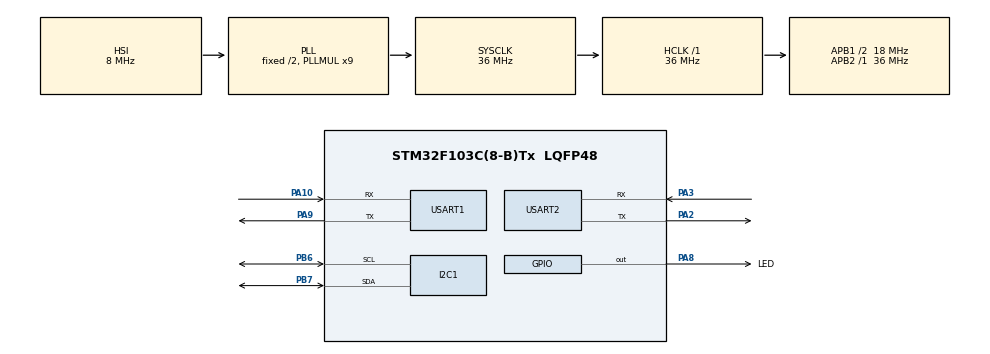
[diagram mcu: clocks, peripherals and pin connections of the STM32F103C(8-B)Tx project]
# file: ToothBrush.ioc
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Dma.Request0=USART1_TX
Dma.Request1=USART2_TX
Dma.USART1_TX.0.Direction=DMA_MEMORY_TO_PERIPH
Dma.USART1_TX.0.Instance=DMA1_Channel4
Dma.USART1_TX.0.MemDataAlignment=DMA_MDATAALIGN_BYTE
Dma.USART1_TX.0.MemInc=DMA_MINC_ENABLE
Dma.USART1_TX.0.Mode=DMA_NORMAL
Dma.USART1_TX.0.PeriphDataAlignment=DMA_PDATAALIGN_BYTE
Dma.USART1_TX.0.PeriphInc=DMA_PINC_DISABLE
Dma.USART1_TX.0.Priority=DMA_PRIORITY_LOW
Dma.USART2_TX.1.Direction=DMA_MEMORY_TO_PERIPH
Dma.USART2_TX.1.Instance=DMA1_Channel7
Dma.USART2_TX.1.MemDataAlignment=DMA_MDATAALIGN_BYTE
Dma.USART2_TX.1.MemInc=DMA_MINC_ENABLE
Dma.USART2_TX.1.Mode=DMA_NORMAL
Dma.USART2_TX.1.PeriphDataAlignment=DMA_PDATAALIGN_BYTE
Dma.USART2_TX.1.PeriphInc=DMA_PINC_DISABLE
Dma.USART2_TX.1.Priority=DMA_PRIORITY_LOW
FREERTOS.INCLUDE_xTaskAbortDelay=0
FREERTOS.INCLUDE_xTaskGetHandle=0
FREERTOS.MEMORY_ALLOCATION=0
FREERTOS.Tasks01=defaultTask,0,128,StartDefaultTask,Default,NULL
FREERTOS.configUSE_DAEMON_TASK_STARTUP_HOOK=0
I2C1.DutyCycle=I2C_DUTYCYCLE_2
Mcu.Family=STM32F1
Mcu.Name=STM32F103C(8-B)Tx
Mcu.Package=LQFP48
NVIC.DMA1_Channel4_IRQn=true\:5\:0\:false\:false\:true\:true
NVIC.DMA1_Channel7_IRQn=true\:5\:0\:false\:false\:true\:true
NVIC.PriorityGroup=NVIC_PRIORITYGROUP_4
NVIC.USART1_IRQn=true\:5\:0\:false\:false\:true\:true
NVIC.USART2_IRQn=true\:5\:0\:false\:false\:true\:true
PA10.Mode=Asynchronous
PA10.Signal=USART1_RX
PA2.Mode=Asynchronous
PA2.Signal=USART2_TX
PA3.Mode=Asynchronous
PA3.Signal=USART2_RX
PA8.GPIO_Label=LED
PA8.Signal=GPIO_Output
PA9.Mode=Asynchronous
PA9.Signal=USART1_TX
PB6.Mode=I2C
PB6.Signal=I2C1_SCL
PB7.Mode=I2C
PB7.Signal=I2C1_SDA
ProjectManager.HeapSize=0x200
ProjectManager.StackSize=0x400
ProjectManager.TargetToolchain=MDK-ARM V5
RCC.AHBCLKDivider=RCC_SYSCLK_DIV1
RCC.AHBFreq_Value=36000000
RCC.APB1CLKDivider=RCC_HCLK_DIV2
RCC.APB1Freq_Value=18000000
RCC.APB1TimFreq_Value=36000000
RCC.APB2CLKDivider=RCC_HCLK_DIV1
RCC.APB2Freq_Value=36000000
RCC.APB2TimFreq_Value=36000000
RCC.ClockTypeHCLK=RCC_CLOCKTYPE_HCLK
RCC.ClockTypePCLK1=RCC_CLOCKTYPE_PCLK1
RCC.ClockTypePCLK2=RCC_CLOCKTYPE_PCLK2
RCC.EnableHSE=false
RCC.EnableHSERTCDevisor=false
RCC.EnableLSE=false
RCC.EnableLSERTC=false
RCC.EnableMCOMultDivisor=false
RCC.HCLKFreq_Value=36000000
RCC.HSEState=RCC_HSE_OFF
RCC.HSIState=RCC_HSI_ON
RCC.IWDGEnable=false
RCC.LSIState=RCC_LSI_OFF
RCC.MCOEnable=false
RCC.OscillatorTypeHSI=RCC_OSCILLATORTYPE_HSI
RCC.PLLMUL=RCC_PLL_MUL9
RCC.PLLSource=RCC_PLLSOURCE_HSI_DIV2
RCC.PLLState=RCC_PLL_ON
RCC.RTCEnable=false
RCC.SYSCLKFreq_VALUE=36000000
RCC.SYSCLKSource=RCC_SYSCLKSOURCE_PLLCLK
RCC.TimSys_Div=SYSTICK_CLKSOURCE_HCLK
RCC.USBFreq_Value=36000000
USART1.HwFlowCtl-Asynchronous=UART_HWCONTROL_NONE
USART1.VirtualMode=VM_ASYNC
USART2.HwFlowCtl-Asynchronous=UART_HWCONTROL_NONE
USART2.VirtualMode=VM_ASYNC
VP_FREERTOS_VS_ENABLE.Mode=Enabled
board=ToothBrush

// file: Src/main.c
/**
 ******************************************************************************
 * File Name          : main.c
 * Description        : Main program body
 ******************************************************************************
 *
 * Copyright (c) 2019 STMicroelectronics International N.V.
 * All rights reserved.
 *
 * Redistribution and use in source and binary forms, with or without
 * modification, are permitted, provided that the following conditions are met:
 *
 * 1. Redistribution of source code must retain the above copyright notice,
 *    this list of conditions and the following disclaimer.
 * 2. Redistributions in binary form must reproduce the above copyright notice,
 *    this list of conditions and the following disclaimer in the documentation
 *    and/or other materials provided with the distribution.
 * 3. Neither the name of STMicroelectronics nor the names of other
 *    contributors to this software may be used to endorse or promote products
 *    derived from this software without specific written permission.
 * 4. This software, including modifications and/or derivative works of this
 *    software, must execute solely and exclusively on microcontroller or
 *    microprocessor devices manufactured by or for STMicroelectronics.
 * 5. Redistribution and use of this software other than as permitted under
 *    this license is void and will automatically terminate your rights under
 *    this license.
 *
 * THIS SOFTWARE IS PROVIDED BY STMICROELECTRONICS AND CONTRIBUTORS "AS IS"
 * AND ANY EXPRESS, IMPLIED OR STATUTORY WARRANTIES, INCLUDING, BUT NOT
 * LIMITED TO, THE IMPLIED WARRANTIES OF MERCHANTABILITY, FITNESS FOR A
 * PARTICULAR PURPOSE AND NON-INFRINGEMENT OF THIRD PARTY INTELLECTUAL PROPERTY
 * RIGHTS ARE DISCLAIMED TO THE FULLEST EXTENT PERMITTED BY LAW. IN NO EVENT
 * SHALL STMICROELECTRONICS OR CONTRIBUTORS BE LIABLE FOR ANY DIRECT, INDIRECT,
 * INCIDENTAL, SPECIAL, EXEMPLARY, OR CONSEQUENTIAL DAMAGES (INCLUDING, BUT NOT
 * LIMITED TO, PROCUREMENT OF SUBSTITUTE GOODS OR SERVICES; LOSS OF USE, DATA,
 * OR PROFITS; OR BUSINESS INTERRUPTION) HOWEVER CAUSED AND ON ANY THEORY OF
 * LIABILITY, WHETHER IN CONTRACT, STRICT LIABILITY, OR TORT (INCLUDING
 * NEGLIGENCE OR OTHERWISE) ARISING IN ANY WAY OUT OF THE USE OF THIS SOFTWARE,
 * EVEN IF ADVISED OF THE POSSIBILITY OF SUCH DAMAGE.
 *
 ******************************************************************************
 */
#include "main.h"
#include "stm32f1xx_hal.h"
#include "cmsis_os.h"

/* USER CODE BEGIN Includes */
#include "user_com.h"

/* USER CODE END Includes */

I2C_HandleTypeDef hi2c1;

UART_HandleTypeDef huart1;
UART_HandleTypeDef huart2;
DMA_HandleTypeDef hdma_usart1_tx;
DMA_HandleTypeDef hdma_usart2_tx;

osThreadId defaultTaskHandle;

/* USER CODE BEGIN PV */
/* Private variables ---------------------------------------------------------*/

/* USER CODE END PV */

void SystemClock_Config(void);
void Error_Handler(void);
static void MX_GPIO_Init(void);
static void MX_DMA_Init(void);
static void MX_USART1_UART_Init(void);
static void MX_USART2_UART_Init(void);
static void MX_I2C1_Init(void);
void StartDefaultTask(void const *argument);

/* USER CODE BEGIN PFP */
/* Private function prototypes -----------------------------------------------*/

/* USER CODE END PFP */

int main(void) {

	/* MCU Configuration----------------------------------------------------------*/

	/* Reset of all peripherals, Initializes the Flash interface and the Systick. */
	HAL_Init();

	/* Configure the system clock */
	SystemClock_Config();

	/* Initialize all configured peripherals */
	MX_GPIO_Init();
	MX_DMA_Init();
	MX_USART1_UART_Init();
	MX_USART2_UART_Init();
	MX_I2C1_Init();

	/* Create the thread(s) */
	/* definition and creation of defaultTask */
	osThreadDef(defaultTask, StartDefaultTask, osPriorityNormal, 0, 128)
	;
	defaultTaskHandle = osThreadCreate(osThread(defaultTask), NULL);

	/* Start scheduler */
	osKernelStart();

	/* We should never get here as control is now taken by the scheduler */

	/* Infinite loop */
	while (1) {

	}

}

/** System Clock Configuration
 */
void SystemClock_Config(void) {

	RCC_OscInitTypeDef RCC_OscInitStruct;
	RCC_ClkInitTypeDef RCC_ClkInitStruct;

	/**Initializes the CPU, AHB and APB busses clocks
	 */
	RCC_OscInitStruct.OscillatorType = RCC_OSCILLATORTYPE_HSI;
	RCC_OscInitStruct.HSIState = RCC_HSI_ON;
	RCC_OscInitStruct.HSICalibrationValue = 16;
	RCC_OscInitStruct.PLL.PLLState = RCC_PLL_ON;
	RCC_OscInitStruct.PLL.PLLSource = RCC_PLLSOURCE_HSI_DIV2;
	RCC_OscInitStruct.PLL.PLLMUL = RCC_PLL_MUL9;
	if (HAL_RCC_OscConfig(&RCC_OscInitStruct) != HAL_OK) {
		Error_Handler();
	}

	/**Initializes the CPU, AHB and APB busses clocks
	 */
	RCC_ClkInitStruct.ClockType = RCC_CLOCKTYPE_HCLK | RCC_CLOCKTYPE_SYSCLK | RCC_CLOCKTYPE_PCLK1 | RCC_CLOCKTYPE_PCLK2;
	RCC_ClkInitStruct.SYSCLKSource = RCC_SYSCLKSOURCE_PLLCLK;
	RCC_ClkInitStruct.AHBCLKDivider = RCC_SYSCLK_DIV1;
	RCC_ClkInitStruct.APB1CLKDivider = RCC_HCLK_DIV2;
	RCC_ClkInitStruct.APB2CLKDivider = RCC_HCLK_DIV1;

	if (HAL_RCC_ClockConfig(&RCC_ClkInitStruct, FLASH_LATENCY_1) != HAL_OK) {
		Error_Handler();
	}

	/**Configure the Systick interrupt time
	 */
	HAL_SYSTICK_Config(HAL_RCC_GetHCLKFreq() / 1000);

	/**Configure the Systick
	 */
	HAL_SYSTICK_CLKSourceConfig(SYSTICK_CLKSOURCE_HCLK);

	/* SysTick_IRQn interrupt configuration */
	HAL_NVIC_SetPriority(SysTick_IRQn, 15, 0);
}

/* I2C1 init function */
static void MX_I2C1_Init(void) {

	hi2c1.Instance = I2C1;
	hi2c1.Init.ClockSpeed = 100000;
	hi2c1.Init.DutyCycle = I2C_DUTYCYCLE_2;
	hi2c1.Init.OwnAddress1 = 0;
	hi2c1.Init.AddressingMode = I2C_ADDRESSINGMODE_7BIT;
	hi2c1.Init.DualAddressMode = I2C_DUALADDRESS_DISABLE;
	hi2c1.Init.OwnAddress2 = 0;
	hi2c1.Init.GeneralCallMode = I2C_GENERALCALL_DISABLE;
	hi2c1.Init.NoStretchMode = I2C_NOSTRETCH_DISABLE;
	if (HAL_I2C_Init(&hi2c1) != HAL_OK) {
		Error_Handler();
	}

}

/* USART1 init function */
static void MX_USART1_UART_Init(void) {

	huart1.Instance = USART1;
	huart1.Init.BaudRate = 115200;
	huart1.Init.WordLength = UART_WORDLENGTH_8B;
	huart1.Init.StopBits = UART_STOPBITS_1;
	huart1.Init.Parity = UART_PARITY_NONE;
	huart1.Init.Mode = UART_MODE_TX_RX;
	huart1.Init.HwFlowCtl = UART_HWCONTROL_NONE;
	huart1.Init.OverSampling = UART_OVERSAMPLING_16;
	if (HAL_UART_Init(&huart1) != HAL_OK) {
		Error_Handler();
	}

}

/* USART2 init function */
static void MX_USART2_UART_Init(void) {

	huart2.Instance = USART2;
	huart2.Init.BaudRate = 115200;
	huart2.Init.WordLength = UART_WORDLENGTH_8B;
	huart2.Init.StopBits = UART_STOPBITS_1;
	huart2.Init.Parity = UART_PARITY_NONE;
	huart2.Init.Mode = UART_MODE_TX_RX;
	huart2.Init.HwFlowCtl = UART_HWCONTROL_NONE;
	huart2.Init.OverSampling = UART_OVERSAMPLING_16;
	if (HAL_UART_Init(&huart2) != HAL_OK) {
		Error_Handler();
	}

}

static void MX_DMA_Init(void) {
	/* DMA controller clock enable */
	__HAL_RCC_DMA1_CLK_ENABLE();

	/* DMA interrupt init */
	/* DMA1_Channel4_IRQn interrupt configuration */
	HAL_NVIC_SetPriority(DMA1_Channel4_IRQn, 5, 0);
	HAL_NVIC_EnableIRQ(DMA1_Channel4_IRQn);
	/* DMA1_Channel7_IRQn interrupt configuration */
	HAL_NVIC_SetPriority(DMA1_Channel7_IRQn, 5, 0);
	HAL_NVIC_EnableIRQ(DMA1_Channel7_IRQn);

}

/** Configure pins as
 * Analog
 * Input
 * Output
 * EVENT_OUT
 * EXTI
 */
static void MX_GPIO_Init(void) {

	GPIO_InitTypeDef GPIO_InitStruct;

	/* GPIO Ports Clock Enable */
	__HAL_RCC_GPIOA_CLK_ENABLE();
	__HAL_RCC_GPIOB_CLK_ENABLE();

	/*Configure GPIO pin Output Level */
	HAL_GPIO_WritePin(LED_GPIO_Port, LED_Pin, GPIO_PIN_RESET);

	/*Configure GPIO pin : LED_Pin */
	GPIO_InitStruct.Pin = LED_Pin;
	GPIO_InitStruct.Mode = GPIO_MODE_OUTPUT_PP;
	GPIO_InitStruct.Speed = GPIO_SPEED_FREQ_LOW;
	HAL_GPIO_Init(LED_GPIO_Port, &GPIO_InitStruct);

}

/* StartDefaultTask function */
void StartDefaultTask(void const *argument) {

	/* USER CODE BEGIN 5 */
    uint8_t* testArr="12345678";

    DBGInit();

    //Mpu6050Init();

	/* Infinite loop */
	for (;;) {
		HAL_Delay(1000);
		DBG_LOG("test");
        //HAL_UART_Transmit_IT(&huart1,testArr,8);
		HAL_GPIO_WritePin(GPIOA, GPIO_PIN_8, GPIO_PIN_RESET);
		HAL_Delay(1000);
		HAL_GPIO_WritePin(GPIOA, GPIO_PIN_8, GPIO_PIN_SET);
	}
	/* USER CODE END 5 */
}

void Error_Handler(void) {
	while (1) {
	}
}

/************************ (C) COPYRIGHT STMicroelectronics *****END OF FILE****/
